# STM32WBA25 register map
File version: 1.0
CPU: CM33 r0p1, little endian, MPU, FPU, 4 interrupt priority bits
Registers are 32-bit, read-write, reset 0x0 unless marked. A register's access mark holds for its fields unless they carry their own. Offsets are from the block's base; [hi:lo] are bit positions; {n}, {i} and the like mark numbered series.

## AES — AES register block
Base 0x420C0000
Same registers: SEC_AES 0x520C0000
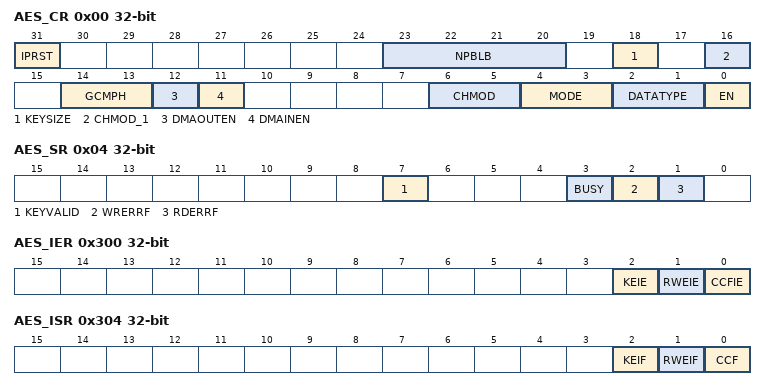
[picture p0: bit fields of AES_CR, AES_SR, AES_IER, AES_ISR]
0x00 AES_CR — AES control register
  [31] IPRST — AES peripheral software reset
  [23:20] NPBLB — Number of padding bytes in last block
    0=All bytes are valid (no padding); 1=Padding for the last LSB byte; 15=Padding for the 15 LSB bytes of last block
  [18] KEYSIZE — Key size selection
    0=128-bit; 1=256-bit
  [16] CHMOD_1 — CHMOD[2]
  [14:13] GCMPH — GCM or CCM phase selection
    0=Initialization phase; 1=Header phase; 2=Payload phase; 3=Final phase
  [12] DMAOUTEN — DMA output enable
    0=DMA for outgoing data transfer is disabled; 1=DMA for outgoing data transfer is enabled
  [11] DMAINEN — DMA input enable
    0=DMA for incoming data transfer is disabled; 1=DMA for incoming data transfer is enabled
  [6:5] CHMOD — CHMOD[1:0]: Chaining mode
    0=Electronic codebook (ECB); 1=Cipher-block chaining (CBC); 2=Counter mode (CTR); 3=Galois counter mode (GCM) and Galois message authentication code (GMAC)
  [4:3] MODE — Operating mode
    0=Encryption; 1=Key derivation (or key preparation), for ECB/CBC decryption only; 2=Decryption
  [2:1] DATATYPE
    0=No swapping (32-bit data); 1=Half-word swapping (16-bit data); 2=Byte swapping (8-bit data); 3=Bit-level swapping
  [0] EN — Enable
    0=Disable; 1=Enable
0x04 AES_SR ro — AES status register
  [7] KEYVALID — Key valid flag
    0=Key not valid; 1=Key valid
  [3] BUSY
    0=Idle; 1=Busy
  [2] WRERRF — Write error flag
    0=No error; 1=Unexpected write to AES_DINR register occurred during computation or data output phase
  [1] RDERRF — Read error flag
    0=No error; 1=Unexpected read to AES_DOUTR register occurred during computation or data input phase
0x08 AES_DINR wo — AES data input register
  [31:0] DIN — Input data word
0x0C AES_DOUTR ro — AES data output register
  [31:0] DOUT — Output data word
{0x10+4i} AES_KEYR{i} wo (i=0..3) — AES key register {i}
  [31:0] KEY — Cryptographic key, bits [{32i+31}:{32i}]
{0x20+4i} AES_IVR{i} (i=0..3) — AES initialization vector register {i}
  [31:0] IVI — Initialization vector input, bits [{32i+31}:{32i}]
{0x20+4i} AES_KEYR{i} wo (i=4..7) — AES key register {i}
  [31:0] KEY — Cryptographic key, bits [{32i+31}:{32i}]
{0x40+4i} AES_SUSPR{i} (i=0..7) — AES suspend registers
  [31:0] SUSP — Suspend data
0x300 AES_IER — AES interrupt enable register
  [all] fields
    0=Disabled (masked); 1=Enabled (not masked)
  [2] KEIE — Key error interrupt enable
  [1] RWEIE — Read or write error interrupt enable
  [0] CCFIE — Computation complete flag interrupt enable
0x304 AES_ISR ro — AES interrupt status register
  [2] KEIF — Key error interrupt flag
    0=No key error detected; 1=Key information failed to load into key registers
  [1] RWEIF — Read or write error interrupt flag
    0=No read or write error detected; 1=Read or write error detected (see AES_SR register for details)
  [0] CCF — Computation complete flag
    0=Not completed; 1=Completed
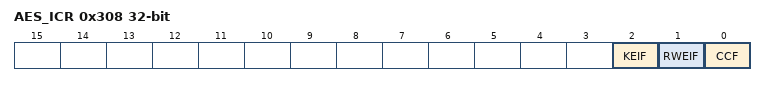
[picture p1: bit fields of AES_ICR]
0x308 AES_ICR wo — AES interrupt clear register
  [2] KEIF — Key error interrupt flag clear
  [1] RWEIF — Read or write error interrupt flag clear
  [0] CCF — Computation complete flag clear

## CRC — CRC address block description
Base 0x40023000
Same registers: SEC_CRC 0x50023000
0x00 CRC_DR reset 0xFFFFFFFF — CRC data register
  [31:0] DR — Data register bits
0x04 CRC_IDR — CRC independent data register
  [31:0] IDR — General-purpose 32-bit data register bits
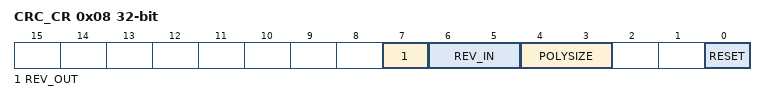
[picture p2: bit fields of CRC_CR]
0x08 CRC_CR — CRC control register
  [7] REV_OUT — Reverse output data
    0=Bit order not affected; 1=Bit-reversed output format
  [6:5] REV_IN — Reverse input data
    0=Bit order not affected; 1=Bit reversal done by byte; 2=Bit reversal done by half-word; 3=Bit reversal done by word
  [4:3] POLYSIZE — Polynomial size
    0=32 bit polynomial; 1=16 bit polynomial; 2=8 bit polynomial; 3=7 bit polynomial
  [0] RESET — RESET bit
0x10 CRC_INIT reset 0xFFFFFFFF — CRC initial value
  [31:0] CRC_INIT — Programmable initial CRC value
0x14 CRC_POL reset 0x4C11DB7 — CRC polynomial
  [31:0] POL — Programmable polynomial
